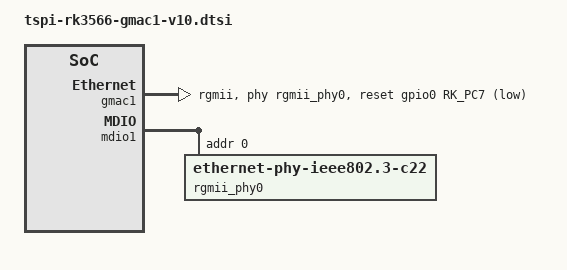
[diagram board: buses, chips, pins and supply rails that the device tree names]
/*********************************************************************
 *           立创开发板不靠卖板赚钱，以培养中国工程师为己任  
 *         泰山派软硬件资料与相关扩展板软硬件资料官网全部开源
 *                      开发板官网：www.lckfb.com            
 *                     立创论坛：oshwhub.com/forum           
 *            关注B站：【立创开发板】，掌握我们的最新动态！  
 *********************************************************************
 * 文件名：tspi-rk3566-gmac1-v10.dtsi
 * 描述：网口配置
 * 更新:
 * 时间          作者           联系           说明
 * 2023-09-13   吴才成    1378913492@qq.com   v1.0.0
 *********************************************************************/



&gmac1 {
	phy-mode = "rgmii";
	clock_in_out = "output";

	snps,reset-gpio = <&gpio0 RK_PC7 GPIO_ACTIVE_LOW>;
	snps,reset-active-low;
	/* Reset time is 20ms, 100ms for rtl8211f */
	snps,reset-delays-us = <0 20000 100000>;

	assigned-clocks = <&cru SCLK_GMAC1_RX_TX>, <&cru SCLK_GMAC1>;
	assigned-clock-parents = <&cru SCLK_GMAC1_RGMII_SPEED>, <&cru CLK_MAC1_2TOP>;
	assigned-clock-rates = <0>, <125000000>;

	pinctrl-names = "default";
	pinctrl-0 = <&gmac1m1_miim
		     &gmac1m1_tx_bus2
		     &gmac1m1_rx_bus2
		     &gmac1m1_rgmii_clk
		     &gmac1m1_rgmii_bus>;

	tx_delay = <0x4f>;
	rx_delay = <0x25>;

	phy-handle = <&rgmii_phy0>;
	status = "okay";
};

&mdio1 {
	rgmii_phy0: phy@0 {
		compatible = "ethernet-phy-ieee802.3-c22";
		reg = <0x0>;
	};
};
